# STM32F745IEK6 register map
File version: 1.0
Registers are 32-bit, access not given, reset 0x0 unless marked. A register's access mark holds for its fields unless they carry their own. Offsets are from the block's base; [hi:lo] are bit positions; {n}, {i} and the like mark numbered series; 'fields as' and 'values as' point back to an identical list.

## TIM6
Base 0x40001000
Same registers: TIM7 0x40001400
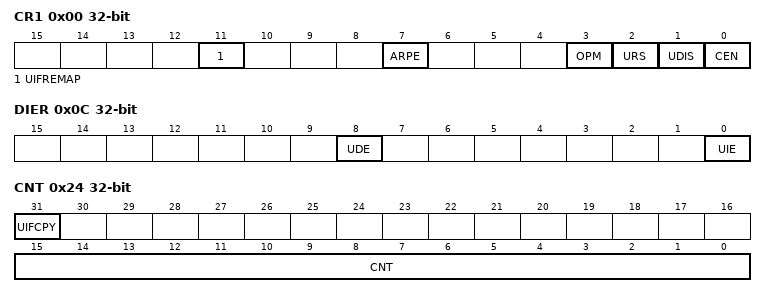
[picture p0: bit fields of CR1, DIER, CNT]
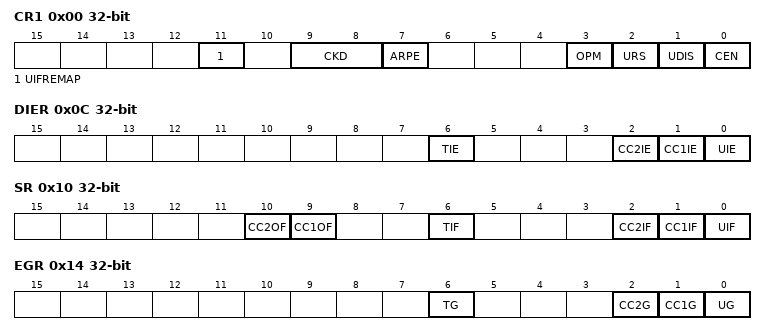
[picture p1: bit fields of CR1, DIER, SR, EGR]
0x00 CR1
  [11] UIFREMAP, [7] ARPE, [3] OPM, [2] URS, [1] UDIS, [0] CEN
0x04 CR2
  [6:4] MMS
0x0C DIER
  [8] UDE, [0] UIE
0x10 SR
  [0] UIF
0x14 EGR
  [0] UG
0x24 CNT
  [31] UIFCPY, [15:0] CNT
0x28 PSC
  [15:0] PSC
0x2C ARR
  [15:0] ARR

## TIM12
Base 0x40001800
Same registers: TIM9 0x40014000
0x00 CR1
  [11] UIFREMAP, [9:8] CKD, [7] ARPE, [3] OPM, [2] URS, [1] UDIS, [0] CEN
0x08 SMCR
  [7] MSM, [6:4] TS, [16:0] SMS
0x0C DIER
  [6] TIE, [2] CC2IE, [1] CC1IE, [0] UIE
0x10 SR
  [10] CC2OF, [9] CC1OF, [6] TIF, [2] CC2IF, [1] CC1IF, [0] UIF
0x14 EGR
  [6] TG, [2] CC2G, [1] CC1G, [0] UG
0x18 CCMR1_Output
  [24:12] OC2M, [11] OC2PE, [10] OC2FE, [9:8] CC2S, [16:4] OC1M, [3] OC1PE, [2] OC1FE, [1:0] CC1S
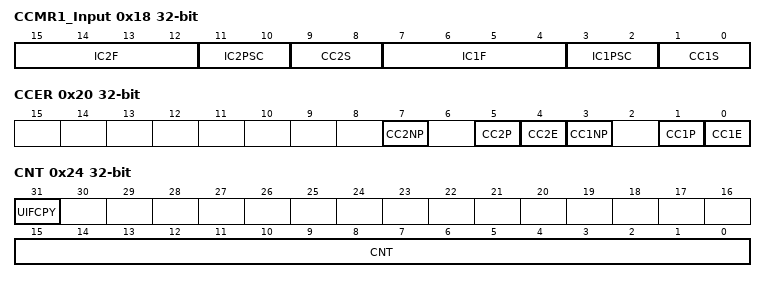
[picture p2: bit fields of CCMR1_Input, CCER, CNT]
0x18 CCMR1_Input
  [15:12] IC2F, [11:10] IC2PSC, [9:8] CC2S, [7:4] IC1F, [3:2] IC1PSC, [1:0] CC1S
0x20 CCER
  [7] CC2NP, [5] CC2P, [4] CC2E, [3] CC1NP, [1] CC1P, [0] CC1E
0x24 CNT
  [31] UIFCPY, [15:0] CNT
0x28 PSC
  [15:0] PSC
0x2C ARR
  [15:0] ARR
0x34 CCR1
  [15:0] CCR1
0x38 CCR2
  [15:0] CCR2

## TIM13
Base 0x40001C00
Same registers: TIM14 0x40002000, TIM10 0x40014400, TIM11 0x40014800
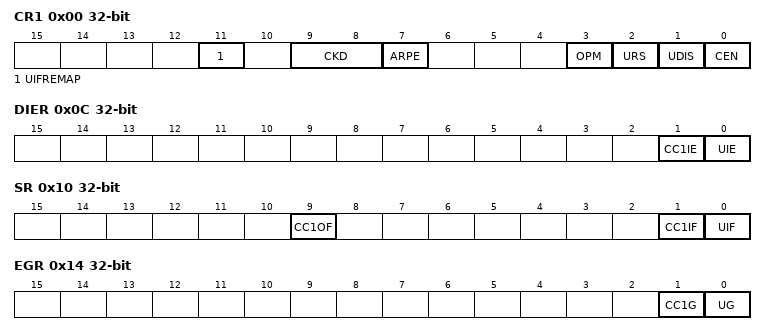
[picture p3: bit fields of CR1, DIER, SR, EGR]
0x00 CR1
  [11] UIFREMAP, [9:8] CKD, [7] ARPE, [3] OPM, [2] URS, [1] UDIS, [0] CEN
0x0C DIER
  [1] CC1IE, [0] UIE
0x10 SR
  [9] CC1OF, [1] CC1IF, [0] UIF
0x14 EGR
  [1] CC1G, [0] UG
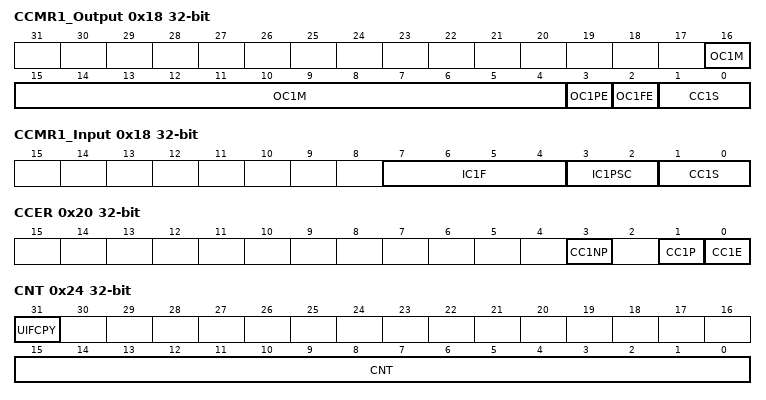
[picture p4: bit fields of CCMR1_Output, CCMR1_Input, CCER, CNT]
0x18 CCMR1_Output
  [16:4] OC1M, [3] OC1PE, [2] OC1FE, [1:0] CC1S
0x18 CCMR1_Input
  [7:4] IC1F, [3:2] IC1PSC, [1:0] CC1S
0x20 CCER
  [3] CC1NP, [1] CC1P, [0] CC1E
0x24 CNT
  [31] UIFCPY, [15:0] CNT
0x28 PSC
  [15:0] PSC
0x2C ARR
  [15:0] ARR
0x34 CCR1
  [15:0] CCR1
0x50 OR
  [1:0] TI1_RMP

## LPTIM1
Base 0x40002400
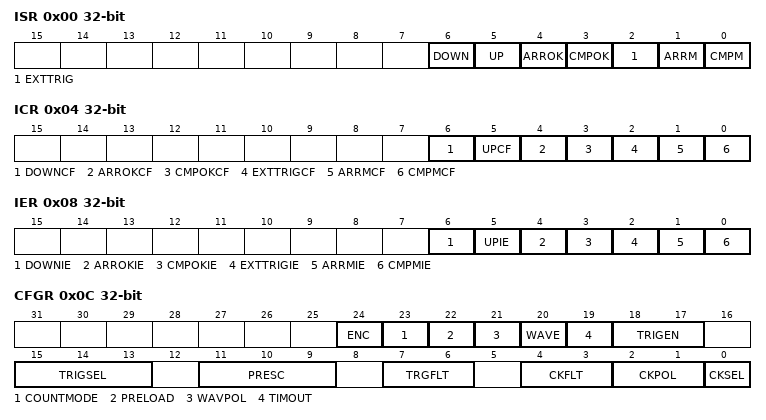
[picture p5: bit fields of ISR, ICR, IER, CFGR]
0x00 ISR
  [6] DOWN, [5] UP, [4] ARROK, [3] CMPOK, [2] EXTTRIG, [1] ARRM, [0] CMPM
0x04 ICR
  [6] DOWNCF, [5] UPCF, [4] ARROKCF, [3] CMPOKCF, [2] EXTTRIGCF, [1] ARRMCF, [0] CMPMCF
0x08 IER
  [6] DOWNIE, [5] UPIE, [4] ARROKIE, [3] CMPOKIE, [2] EXTTRIGIE, [1] ARRMIE, [0] CMPMIE
0x0C CFGR
  [24] ENC, [23] COUNTMODE, [22] PRELOAD, [21] WAVPOL, [20] WAVE, [19] TIMOUT, [18:17] TRIGEN, [15:13] TRIGSEL, [11:9] PRESC, [7:6] TRGFLT, [4:3] CKFLT, [2:1] CKPOL, [0] CKSEL
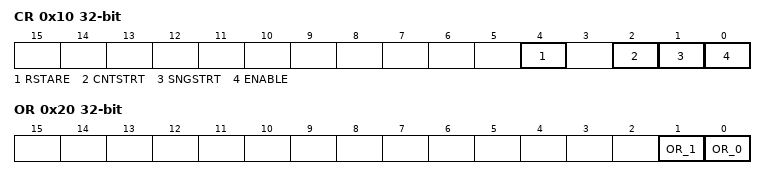
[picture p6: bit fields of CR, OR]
0x10 CR
  [4] RSTARE, [2] CNTSTRT, [1] SNGSTRT, [0] ENABLE
0x14 CMP
  [15:0] CMP
0x18 ARR
  [15:0] ARR
0x1C CNT
  [15:0] CNT
0x20 OR
  [1] OR_1, [0] OR_0

## RTC
Base 0x40002800
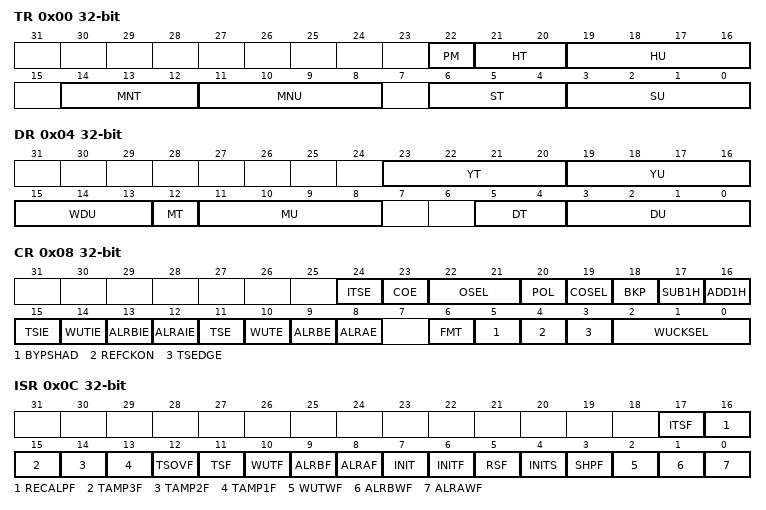
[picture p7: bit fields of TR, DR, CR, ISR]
0x00 TR
  [22] PM, [21:20] HT, [19:16] HU, [14:12] MNT, [11:8] MNU, [6:4] ST, [3:0] SU
0x04 DR
  [23:20] YT, [19:16] YU, [15:13] WDU, [12] MT, [11:8] MU, [5:4] DT, [3:0] DU
0x08 CR
  [24] ITSE, [23] COE, [22:21] OSEL, [20] POL, [19] COSEL, [18] BKP, [17] SUB1H, [16] ADD1H, [15] TSIE, [14] WUTIE, [13] ALRBIE, [12] ALRAIE, [11] TSE, [10] WUTE, [9] ALRBE, [8] ALRAE, [6] FMT, [5] BYPSHAD, [4] REFCKON, [3] TSEDGE, [2:0] WUCKSEL
0x0C ISR
  [17] ITSF, [16] RECALPF, [15] TAMP3F, [14] TAMP2F, [13] TAMP1F, [12] TSOVF, [11] TSF, [10] WUTF, [9] ALRBF, [8] ALRAF, [7] INIT, [6] INITF, [5] RSF, [4] INITS, [3] SHPF, [2] WUTWF, [1] ALRBWF, [0] ALRAWF
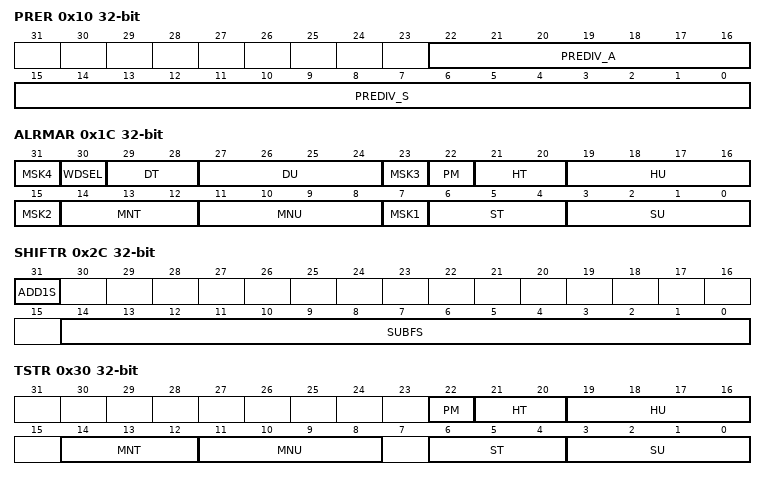
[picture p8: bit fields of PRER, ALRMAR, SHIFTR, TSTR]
0x10 PRER
  [22:16] PREDIV_A, [15:0] PREDIV_S
0x14 WUTR
  [15:0] WUT
0x1C ALRMAR
  [8n-1] MSK{n} (n=1..4), [30] WDSEL, [29:28] DT, [27:24] DU, [22] PM, [21:20] HT, [19:16] HU, [14:12] MNT, [11:8] MNU, [6:4] ST, [3:0] SU
0x20 ALRMBR
  [31] MSK4, [30] WDSEL, [29:28] DT, [27:24] DU, [23] MSK3, [22] PM, [21:20] HT, [19:16] HU, [14:12] MNT, [11:8] MNU, [15:7] MSK2, [6:4] ST, [3:0] SU
0x24 WPR
  [7:0] KEY
0x28 SSR
  [15:0] SS
0x2C SHIFTR
  [31] ADD1S, [14:0] SUBFS
0x30 TSTR
  fields as TR
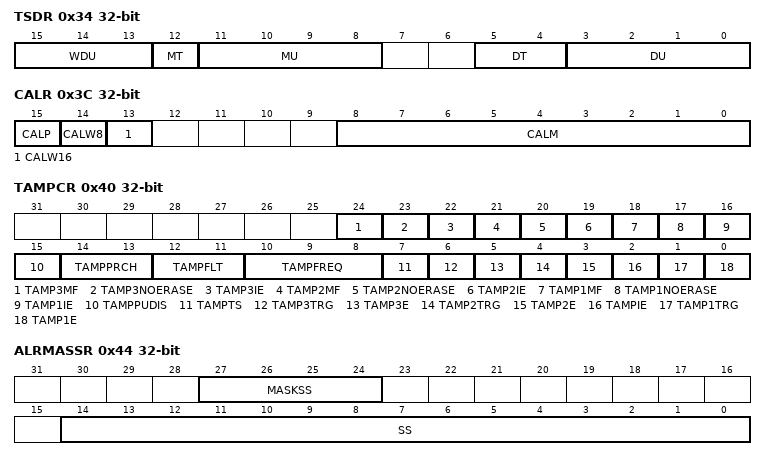
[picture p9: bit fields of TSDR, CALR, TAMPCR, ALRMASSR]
0x34 TSDR
  [15:13] WDU, [12] MT, [11:8] MU, [5:4] DT, [3:0] DU
0x38 TSSSR
  [15:0] SS
0x3C CALR
  [15] CALP, [14] CALW8, [13] CALW16, [8:0] CALM
0x40 TAMPCR
  [24] TAMP3MF, [23] TAMP3NOERASE, [22] TAMP3IE, [21] TAMP2MF, [20] TAMP2NOERASE, [19] TAMP2IE, [18] TAMP1MF, [17] TAMP1NOERASE, [16] TAMP1IE, [15] TAMPPUDIS, [14:13] TAMPPRCH, [12:11] TAMPFLT, [10:8] TAMPFREQ, [7] TAMPTS, [6] TAMP3TRG, [5] TAMP3E, [4] TAMP2TRG, [3] TAMP2E, [2] TAMPIE, [1] TAMP1TRG, [0] TAMP1E
0x44 ALRMASSR
  [27:24] MASKSS, [14:0] SS
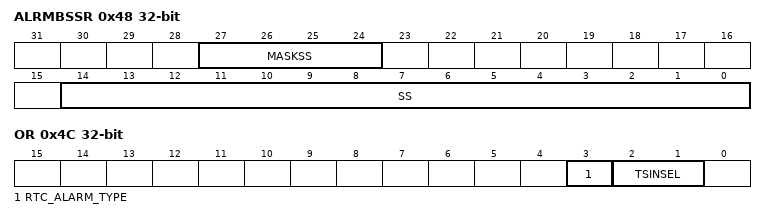
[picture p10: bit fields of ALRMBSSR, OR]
0x48 ALRMBSSR
  [27:24] MASKSS, [14:0] SS
0x4C OR
  [3] RTC_ALARM_TYPE, [2:1] TSINSEL
{0x50+4i} BKP{i}R (i=0..31)
  [31:0] BKP

## BKP
Base 0x40002800
Registers as RTC; these are added or differ:
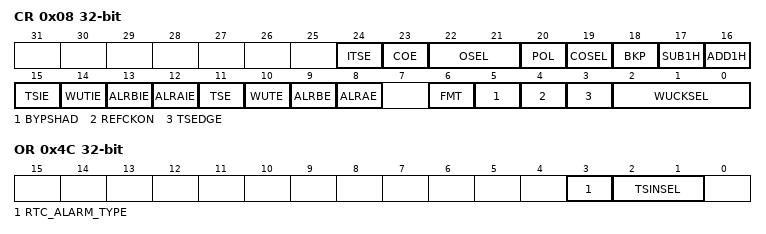
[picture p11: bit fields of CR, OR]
0x08 CR
  fields as RTC.CR
0x4C OR
  [3] RTC_ALARM_TYPE, [2:1] TSINSEL
{0x50+4i} BKP{i}R (i=0..31)
  [31:0] BKP
